AUTOSAR XML (schema 4-2-2)
package /EB/SoftwareComponents
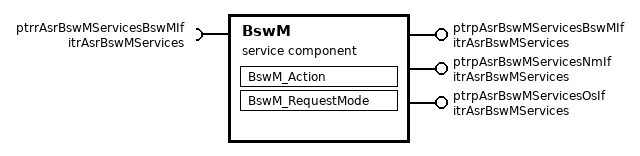
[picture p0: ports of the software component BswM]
  service sw component type BswM: category=ASR_Interfaces
    provide port ptrpAsrBswMServicesBswMIf: provided-interface=itrAsrBswMServices
    provide port ptrpAsrBswMServicesNmIf: provided-interface=itrAsrBswMServices
    provide port ptrpAsrBswMServicesOsIf: provided-interface=itrAsrBswMServices
    require port ptrrAsrBswMServicesBswMIf: required-interface=itrAsrBswMServices
    behavior BswM_IB: handle-termination-and-restart=NO-SUPPORT
      external trigger occurred event trBswM_OnStartupTwoA: start-on-event=BswM_Action, trigger=ptrrAsrBswMServicesBswMIf.BswM_OnStartupTwoA
      external trigger occurred event trBswM_OnStartupTwoB: start-on-event=BswM_Action, trigger=ptrrAsrBswMServicesBswMIf.BswM_OnStartupTwoB
      runnable BswM_Action
      runnable BswM_RequestMode: external-triggering-point=ptrpAsrBswMServicesOsIf.BswM_RequestMode
package /EB/TriggerInterfaces
  trigger interface itrAsrBswMServices
    24 x trigger, all with trigger-period={cse-code=1000, cse-code-factor=0}:
      BswM_HWResetNotification
      BswM_JumpToFBLNotification
      BswM_OnDisableTxPdu
      BswM_OnEnableTxPdu
      BswM_OnGoOffOneA
      BswM_OnLowPwrFromPostRun
      BswM_OnPostRunFromRun
      BswM_OnRunFromLowPwrBusAvailable
      BswM_OnRunFromLowPwrPassengerDetected
      BswM_OnRunFromPostRunBusAvailable
      BswM_OnRunFromPostRunPassengerDetected
      BswM_OnRunFromSafeState
      BswM_OnRunFromWakeup
      BswM_OnSafeStateFromPostRun
      BswM_OnStartComEffective
      BswM_OnStartupTwoA
      BswM_OnStartupTwoB
      BswM_OnWakeupExpired
      BswM_OnWakeupValidation
      BswM_On_Prep_Shutdown
      BswM_ProceedReset
      BswM_ProcessModeFromRun
      BswM_RequestMode
      BswM_SWResetNotification
